# LargeDummyDevice register map
File version: 1.0
Registers are 32-bit, read-write, no defined reset value unless marked. A register's access mark holds for its fields unless they carry their own. Offsets are from the block's base; [hi:lo] are bit positions.

## PERIPHERAL_45
Base 0x4002C000
0x04 REG_1 — Register 1
  [31:30] FIELD_1, [27] FIELD_17, [28:26] FIELD_18, [24:21] FIELD_11, [23:20] FIELD_5, [24:20] FIELD_21, [20:18] FIELD_2, [17] FIELD_19, [16] FIELD_9, [15] FIELD_13, [16:14] FIELD_7, [13] FIELD_4, [11:10] FIELD_3, [10:9] FIELD_6, [9] FIELD_10, [10:9] FIELD_14, [8:6] FIELD_16, [4] FIELD_12, [7:3] FIELD_20, [1:0] FIELD_8, [2:0] FIELD_15, [3:0] FIELD_22
0x08 REG_2 — Register 2
  [32:30] FIELD_8, [30:29] FIELD_4, [29:27] FIELD_1, [26:25] FIELD_6, [24] FIELD_5, [26:23] FIELD_3, [23] FIELD_10, [22:21] FIELD_14, [21:20] FIELD_16, [23:20] FIELD_17, [22:19] FIELD_2, [21:19] FIELD_12, [17:16] FIELD_11, [14:12] FIELD_15, [14:11] FIELD_7, [9] FIELD_13, [6:5] FIELD_9
0x0C REG_3 — Register 3
  [31:27] FIELD_2, [29:26] FIELD_4, [27:25] FIELD_5, [27:24] FIELD_9, [24:22] FIELD_7, [20:19] FIELD_6, [16] FIELD_3, [10:9] FIELD_1, [8:7] FIELD_8
0x10 REG_4 — Register 4
  [32:31] FIELD_13, [28] FIELD_6, [26:25] FIELD_24, [28:24] FIELD_7, [26:24] FIELD_12, [27:24] FIELD_22, [23] FIELD_16, [22:21] FIELD_5, [21:19] FIELD_1, [20:19] FIELD_8, [23:19] FIELD_11, [21:19] FIELD_17, [18] FIELD_25, [20:18] FIELD_27, [16:12] FIELD_19, [14:10] FIELD_9, [11:10] FIELD_10, [13:10] FIELD_15, [9] FIELD_21, [8] FIELD_20, [11:7] FIELD_2, [9:5] FIELD_3, [5] FIELD_23, [7:4] FIELD_4, [6:3] FIELD_26, [1] FIELD_18, [3:0] FIELD_14
0x14 REG_5 — Register 5
  [32:31] FIELD_15, [35:31] FIELD_27, [34:31] FIELD_31, [32:30] FIELD_4, [31:29] FIELD_22, [31:28] FIELD_8, [31:27] FIELD_30, [29:26] FIELD_2, [27:26] FIELD_14, [28:25] FIELD_18, [26:24] FIELD_5, [26:24] FIELD_17, [28:24] FIELD_24, [26:23] FIELD_16, [23:22] FIELD_23, [25:21] FIELD_28, [24:20] FIELD_13, [17:16] FIELD_6, [16:14] FIELD_29, [16:12] FIELD_25, [14:10] FIELD_10, [12:8] FIELD_1, [8:7] FIELD_9, [11:7] FIELD_11, [11:7] FIELD_21, [10:7] FIELD_26, [10:6] FIELD_3, [7:3] FIELD_7, [6:3] FIELD_20, [2] FIELD_12, [1] FIELD_19
0x18 REG_6 — Register 6
  [32:31] FIELD_14, [29] FIELD_13, [31:28] FIELD_26, [29:26] FIELD_6, [27:26] FIELD_21, [24:23] FIELD_2, [26:23] FIELD_4, [19] FIELD_1, [22:19] FIELD_8, [22:19] FIELD_20, [20:18] FIELD_9, [19:17] FIELD_17, [18:16] FIELD_5, [17:15] FIELD_27, [15] FIELD_29, [15:14] FIELD_30, [13] FIELD_3, [15:13] FIELD_18, [13:12] FIELD_31, [10] FIELD_24, [10] FIELD_25, [11:9] FIELD_10, [10:9] FIELD_12, [12:8] FIELD_19, [5] FIELD_23, [7:3] FIELD_15, [4:3] FIELD_28, [3:2] FIELD_16, [2] FIELD_22, [1] FIELD_7, [2:1] FIELD_11
0x1C REG_7 — Register 7
  [31:30] FIELD_5, [30:26] FIELD_2, [29:25] FIELD_4, [23:21] FIELD_1, [24:20] FIELD_7, [11] FIELD_9, [14:10] FIELD_3, [11:10] FIELD_8, [11:9] FIELD_6
0x20 REG_8 — Register 8
  [31:30] FIELD_19, [28:27] FIELD_1, [30:27] FIELD_21, [26:25] FIELD_15, [25:21] FIELD_12, [23:20] FIELD_4, [24:20] FIELD_5, [22:20] FIELD_7, [18:15] FIELD_8, [18:14] FIELD_6, [14] FIELD_20, [14:12] FIELD_10, [12:11] FIELD_14, [11:10] FIELD_3, [12:10] FIELD_18, [11:9] FIELD_9, [11:9] FIELD_11, [7:6] FIELD_2, [6:3] FIELD_13, [6:2] FIELD_16, [5:1] FIELD_17
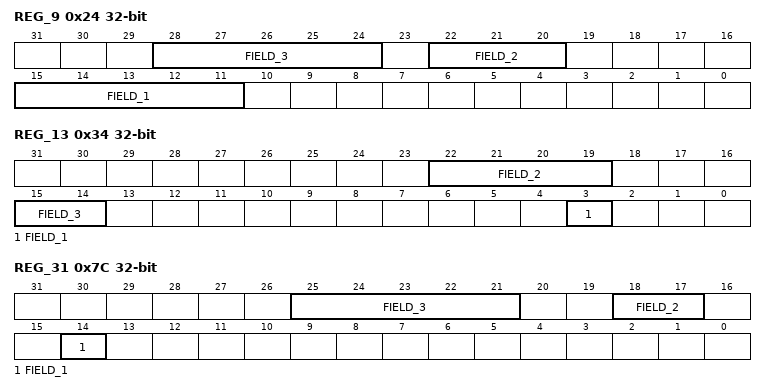
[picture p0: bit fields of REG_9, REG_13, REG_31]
0x24 REG_9 — Register 9
  [28:24] FIELD_3, [22:20] FIELD_2, [15:11] FIELD_1
0x28 REG_10 — Register 10
  [35:31] FIELD_2, [17:14] FIELD_1, [17:13] FIELD_5, [10:7] FIELD_3, [6:2] FIELD_4
0x2C REG_11 — Register 11
  [32:30] FIELD_2, [32:28] FIELD_4, [31:28] FIELD_20, [28:27] FIELD_14, [27:25] FIELD_1, [28:24] FIELD_11, [24:21] FIELD_10, [20] FIELD_3, [22:19] FIELD_12, [20:19] FIELD_18, [21:18] FIELD_15, [17:16] FIELD_22, [16:14] FIELD_13, [15:14] FIELD_21, [16:13] FIELD_8, [14:12] FIELD_17, [12] FIELD_19, [10:8] FIELD_9, [8:7] FIELD_7, [4] FIELD_6, [7:4] FIELD_16, [6:2] FIELD_5
0x30 REG_12 — Register 12
  [30] FIELD_8, [31:29] FIELD_10, [17] FIELD_5, [19:16] FIELD_4, [12:11] FIELD_7, [11:9] FIELD_2, [11:8] FIELD_1, [8] FIELD_9, [4:3] FIELD_3, [2:1] FIELD_6
0x34 REG_13 — Register 13
  [22:19] FIELD_2, [15:14] FIELD_3, [3] FIELD_1
0x38 REG_14 — Register 14
  [31] FIELD_4, [31] FIELD_7, [21] FIELD_6, [19] FIELD_1, [15:11] FIELD_8, [10:9] FIELD_9, [10:8] FIELD_2, [9:7] FIELD_5, [4:0] FIELD_3
0x3C REG_15 — Register 15
  [30:29] FIELD_13, [32:29] FIELD_19, [27:25] FIELD_14, [26:25] FIELD_21, [28:25] FIELD_28, [27:24] FIELD_7, [27:23] FIELD_11, [26:23] FIELD_30, [24:22] FIELD_5, [23:22] FIELD_20, [26:22] FIELD_22, [25:21] FIELD_32, [21:20] FIELD_9, [22:19] FIELD_24, [21:18] FIELD_1, [20:18] FIELD_2, [21:18] FIELD_4, [22:18] FIELD_12, [17] FIELD_15, [20:17] FIELD_16, [14:13] FIELD_23, [15:12] FIELD_10, [14:12] FIELD_29, [14:10] FIELD_3, [9] FIELD_6, [11:8] FIELD_8, [9:6] FIELD_17, [6] FIELD_25, [7:5] FIELD_27, [7:4] FIELD_18, [5:3] FIELD_26, [6:3] FIELD_31
0x40 REG_16 — Register 16
  [32:30] FIELD_2, [31:29] FIELD_3, [30:27] FIELD_15, [26:24] FIELD_14, [28:24] FIELD_16, [28:24] FIELD_17, [23:21] FIELD_1, [17:16] FIELD_11, [14] FIELD_5, [16:14] FIELD_8, [18:14] FIELD_19, [13] FIELD_4, [15:13] FIELD_9, [13:9] FIELD_7, [10:9] FIELD_18, [7] FIELD_6, [6:3] FIELD_13, [1] FIELD_10, [1] FIELD_12
0x44 REG_17 — Register 17
  [30:27] FIELD_4, [31:27] FIELD_6, [24:23] FIELD_8, [20] FIELD_2, [6] FIELD_1, [5:4] FIELD_5, [7:3] FIELD_3, [7:3] FIELD_9, [2:1] FIELD_7
0x48 REG_18 — Register 18
  [33:31] FIELD_1, [35:31] FIELD_14, [27] FIELD_13, [29:25] FIELD_4, [28:25] FIELD_20, [22] FIELD_7, [25:21] FIELD_11, [21:20] FIELD_3, [18] FIELD_8, [22:18] FIELD_15, [22:18] FIELD_16, [19:18] FIELD_19, [17:15] FIELD_5, [14:13] FIELD_21, [16:12] FIELD_10, [11:9] FIELD_9, [9] FIELD_12, [11:8] FIELD_2, [7] FIELD_18, [8:6] FIELD_6, [5:4] FIELD_23, [3] FIELD_22, [5:2] FIELD_24, [3:1] FIELD_17
0x4C REG_19 — Register 19
  [30:28] FIELD_1, [29:27] FIELD_7, [27:26] FIELD_11, [20:19] FIELD_6, [21:18] FIELD_12, [17:15] FIELD_5, [12:9] FIELD_3, [8] FIELD_2, [6:3] FIELD_9, [4:2] FIELD_4, [3:2] FIELD_8, [2] FIELD_10
0x50 REG_20 — Register 20
  [31:27] FIELD_5, [29:26] FIELD_2, [20:19] FIELD_8, [16:14] FIELD_7, [13:10] FIELD_4, [8:6] FIELD_9, [5:2] FIELD_6, [4:1] FIELD_1, [4:0] FIELD_3
0x54 REG_21 — Register 21
  [15:12] FIELD_1
0x58 REG_22 — Register 22
  [33:31] FIELD_1, [31] FIELD_6, [35:31] FIELD_8, [33:29] FIELD_11, [30:27] FIELD_21, [25] FIELD_5, [28:25] FIELD_23, [28:24] FIELD_19, [21] FIELD_18, [25:21] FIELD_24, [20:18] FIELD_3, [18:17] FIELD_20, [18:14] FIELD_2, [17:13] FIELD_13, [12:11] FIELD_17, [13:9] FIELD_14, [10:8] FIELD_10, [9:8] FIELD_22, [8:7] FIELD_9, [10:6] FIELD_15, [4] FIELD_16, [6:3] FIELD_7, [0] FIELD_4, [3:0] FIELD_12
0x5C REG_23 — Register 23
  [30] FIELD_7, [31:29] FIELD_4, [32:29] FIELD_10, [31:27] FIELD_18, [28:26] FIELD_17, [21:20] FIELD_13, [14] FIELD_9, [13:12] FIELD_2, [13:12] FIELD_6, [9] FIELD_5, [10:9] FIELD_8, [11:8] FIELD_1, [12:8] FIELD_3, [9:7] FIELD_11, [11:7] FIELD_12, [10:6] FIELD_15, [6:5] FIELD_14, [5:3] FIELD_20, [3:2] FIELD_16, [4:2] FIELD_19, [3:0] FIELD_21
0x60 REG_24 — Register 24
  [31] FIELD_11, [34:30] FIELD_4, [32:29] FIELD_10, [30:28] FIELD_3, [27:26] FIELD_2, [27:24] FIELD_6, [26:22] FIELD_1, [21:19] FIELD_8, [17] FIELD_7, [15:11] FIELD_9, [4] FIELD_12, [2:1] FIELD_5
0x64 REG_25 — Register 25
  [33:30] FIELD_24, [30:28] FIELD_4, [29:27] FIELD_5, [31:27] FIELD_16, [28:26] FIELD_23, [21] FIELD_12, [21:20] FIELD_17, [19] FIELD_7, [23:19] FIELD_18, [22:19] FIELD_26, [20:18] FIELD_9, [17] FIELD_15, [13] FIELD_6, [14:13] FIELD_14, [10:7] FIELD_13, [7] FIELD_21, [9:6] FIELD_2, [4] FIELD_20, [6:4] FIELD_25, [6:3] FIELD_11, [3] FIELD_19, [5:2] FIELD_3, [2] FIELD_10, [1:0] FIELD_1, [4:0] FIELD_8, [1:0] FIELD_22
0x68 REG_26 — Register 26
  [33:31] FIELD_5, [31] FIELD_8, [33:31] FIELD_19, [28:27] FIELD_6, [31:27] FIELD_12, [28:27] FIELD_28, [27:25] FIELD_30, [25:24] FIELD_2, [24:23] FIELD_23, [21] FIELD_10, [24:20] FIELD_7, [23:20] FIELD_26, [21:19] FIELD_14, [23:19] FIELD_18, [22:18] FIELD_4, [21:18] FIELD_9, [18:17] FIELD_1, [17] FIELD_11, [20:17] FIELD_16, [21:17] FIELD_29, [13:12] FIELD_15, [14:11] FIELD_3, [12:11] FIELD_20, [8:5] FIELD_27, [4] FIELD_24, [6:3] FIELD_13, [5:2] FIELD_25, [1] FIELD_21, [2:1] FIELD_22, [3:0] FIELD_17, [2:0] FIELD_31
0x6C REG_27 — Register 27
  [32:29] FIELD_3, [31:27] FIELD_6, [30:26] FIELD_2, [27:25] FIELD_10, [25:24] FIELD_14, [25:21] FIELD_13, [21:19] FIELD_1, [20:18] FIELD_9, [19:18] FIELD_12, [13] FIELD_16, [16:12] FIELD_5, [11] FIELD_4, [14:10] FIELD_15, [8] FIELD_8, [7:5] FIELD_11, [4:3] FIELD_7
0x70 REG_28 — Register 28
  [35:31] FIELD_5, [32:30] FIELD_1, [30] FIELD_2, [32:30] FIELD_13, [32:29] FIELD_6, [33:29] FIELD_12, [28:27] FIELD_9, [26:25] FIELD_4, [26:25] FIELD_17, [25:23] FIELD_10, [26:23] FIELD_14, [22:19] FIELD_11, [21:18] FIELD_18, [12] FIELD_16, [8:7] FIELD_15, [4] FIELD_3, [4] FIELD_7, [3:2] FIELD_8
0x74 REG_29 — Register 29
  [25:22] FIELD_2, [19:15] FIELD_3, [15:13] FIELD_1
0x78 REG_30 — Register 30
  [30:27] FIELD_1, [28:25] FIELD_9, [25:22] FIELD_13, [23:21] FIELD_3, [23:21] FIELD_10, [20] FIELD_14, [21:19] FIELD_8, [22:18] FIELD_11, [21:17] FIELD_12, [19:17] FIELD_15, [16:12] FIELD_5, [13:12] FIELD_7, [11] FIELD_18, [14:10] FIELD_16, [6] FIELD_6, [6:4] FIELD_2, [2] FIELD_4, [2:1] FIELD_17
0x7C REG_31 — Register 31
  [25:21] FIELD_3, [18:17] FIELD_2, [14] FIELD_1
0x80 REG_32 — Register 32
  [29] FIELD_12, [29:25] FIELD_7, [25:24] FIELD_13, [21] FIELD_10, [22:19] FIELD_8, [23:19] FIELD_11, [18] FIELD_5, [16:12] FIELD_1, [9] FIELD_2, [9] FIELD_6, [6:3] FIELD_9, [5:2] FIELD_4, [0] FIELD_3
0x84 REG_33 — Register 33
  [35:31] FIELD_13, [35:31] FIELD_18, [34:30] FIELD_4, [29] FIELD_3, [31:28] FIELD_5, [27:25] FIELD_28, [23:21] FIELD_9, [25:21] FIELD_22, [21] FIELD_25, [23:20] FIELD_10, [20] FIELD_26, [20:18] FIELD_7, [17] FIELD_19, [15] FIELD_24, [14:13] FIELD_12, [13:12] FIELD_15, [14:12] FIELD_20, [12:11] FIELD_23, [12:10] FIELD_1, [10] FIELD_8, [9] FIELD_27, [7] FIELD_16, [6] FIELD_21, [10:6] FIELD_29, [8:4] FIELD_14, [5:3] FIELD_2, [2] FIELD_6, [5:1] FIELD_11, [4:0] FIELD_17
0x88 REG_34 — Register 34
  [34:31] FIELD_7, [29] FIELD_11, [33:29] FIELD_12, [31:28] FIELD_24, [28:26] FIELD_23, [28:25] FIELD_6, [28:25] FIELD_14, [26:25] FIELD_22, [25:24] FIELD_3, [27:23] FIELD_25, [23:20] FIELD_19, [21:20] FIELD_26, [17:16] FIELD_18, [16] FIELD_21, [12:9] FIELD_10, [11:8] FIELD_27, [10:7] FIELD_9, [8:7] FIELD_13, [9:6] FIELD_4, [9:6] FIELD_20, [9:5] FIELD_2, [4] FIELD_8, [7:3] FIELD_1, [7:3] FIELD_5, [3:2] FIELD_15, [3:0] FIELD_16, [4:0] FIELD_17
0x8C REG_35 — Register 35
  [33:30] FIELD_2, [33:30] FIELD_16, [28] FIELD_6, [25:24] FIELD_32, [24:23] FIELD_7, [22] FIELD_11, [23:21] FIELD_17, [18] FIELD_9, [19:18] FIELD_24, [18:17] FIELD_3, [20:17] FIELD_21, [18:16] FIELD_18, [16:15] FIELD_4, [16:14] FIELD_22, [16:14] FIELD_27, [15:12] FIELD_10, [12:10] FIELD_12, [11:9] FIELD_1, [13:9] FIELD_14, [12:9] FIELD_19, [9:7] FIELD_5, [11:7] FIELD_15, [7] FIELD_23, [10:6] FIELD_8, [9:5] FIELD_28, [7:4] FIELD_20, [8:4] FIELD_30, [7:3] FIELD_13, [6:2] FIELD_26, [4:2] FIELD_29, [5:1] FIELD_31, [0] FIELD_25
0x90 REG_36 — Register 36
  [32:31] FIELD_1, [32:31] FIELD_2, [31:29] FIELD_12, [30:28] FIELD_9, [27:24] FIELD_14, [26:23] FIELD_8, [25:22] FIELD_19, [21] FIELD_7, [22:21] FIELD_13, [20:18] FIELD_20, [21:17] FIELD_6, [16] FIELD_17, [15] FIELD_15, [17:14] FIELD_10, [13] FIELD_16, [11] FIELD_3, [15:11] FIELD_4, [15:11] FIELD_23, [12:8] FIELD_11, [9:5] FIELD_18, [7:5] FIELD_21, [5:2] FIELD_5, [5:2] FIELD_22
0x94 REG_37 — Register 37
  [31:30] FIELD_2, [31:28] FIELD_16, [30:27] FIELD_13, [26:22] FIELD_6, [21] FIELD_1, [25:21] FIELD_4, [20:17] FIELD_7, [17:13] FIELD_10, [14:11] FIELD_15, [15:11] FIELD_18, [13:10] FIELD_17, [11:9] FIELD_12, [10:9] FIELD_19, [8] FIELD_14, [9:6] FIELD_8, [6:3] FIELD_3, [1:0] FIELD_5, [0] FIELD_9, [0] FIELD_11
0x98 REG_38 — Register 38
  [33:30] FIELD_8, [27:23] FIELD_5, [24:22] FIELD_3, [25:21] FIELD_1, [21:20] FIELD_6, [19:16] FIELD_7, [3:2] FIELD_4, [1] FIELD_2
0x9C REG_39 — Register 39
  [32:30] FIELD_9, [29:28] FIELD_7, [27:24] FIELD_5, [27:24] FIELD_20, [26:22] FIELD_4, [22] FIELD_12, [22:21] FIELD_13, [21:18] FIELD_18, [18:17] FIELD_3, [18:15] FIELD_15, [13] FIELD_19, [14:12] FIELD_6, [15:12] FIELD_16, [16:12] FIELD_17, [12:10] FIELD_1, [11:9] FIELD_8, [9:5] FIELD_2, [7:3] FIELD_10, [6:3] FIELD_14, [1:0] FIELD_11
0xA0 REG_40 — Register 40
  [27:26] FIELD_10, [26:23] FIELD_7, [22:21] FIELD_4, [25:21] FIELD_12, [22:18] FIELD_8, [19:16] FIELD_5, [16:14] FIELD_3, [15:13] FIELD_6, [14:12] FIELD_1, [11] FIELD_2, [9:5] FIELD_11, [2] FIELD_9
0xA4 REG_41 — Register 41
  [31] FIELD_13, [33:31] FIELD_17, [32:29] FIELD_29, [29:28] FIELD_10, [27:26] FIELD_7, [26] FIELD_14, [26] FIELD_22, [28:26] FIELD_23, [23] FIELD_6, [21:19] FIELD_20, [19:18] FIELD_16, [19:17] FIELD_12, [16] FIELD_4, [20:16] FIELD_5, [17:16] FIELD_15, [18:16] FIELD_21, [14:12] FIELD_8, [16:12] FIELD_18, [15:12] FIELD_24, [14:12] FIELD_25, [12:11] FIELD_9, [13:11] FIELD_27, [14:10] FIELD_26, [11:10] FIELD_28, [8] FIELD_11, [8:4] FIELD_3, [7:3] FIELD_19, [5:2] FIELD_1, [2:0] FIELD_2
